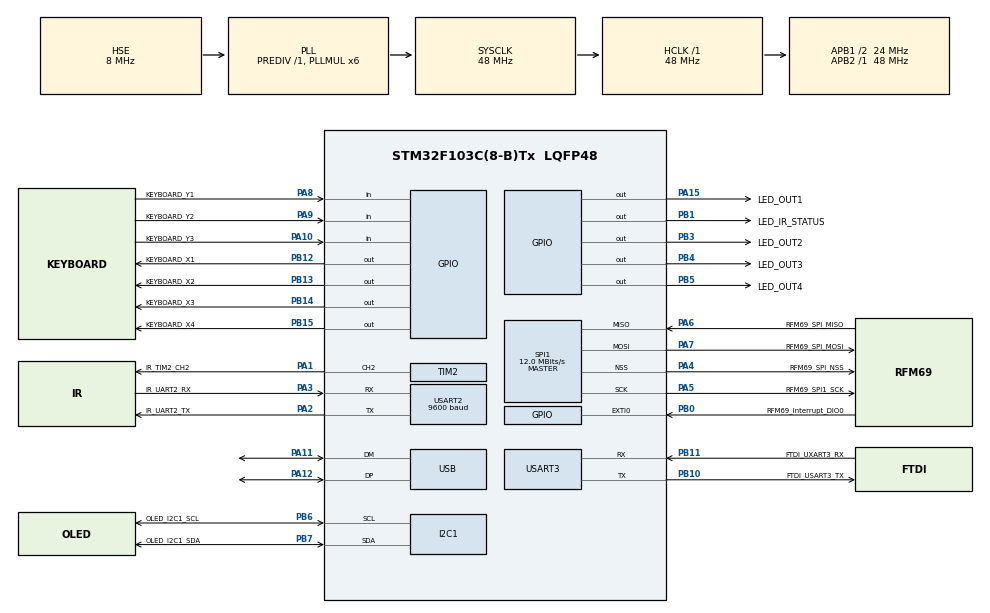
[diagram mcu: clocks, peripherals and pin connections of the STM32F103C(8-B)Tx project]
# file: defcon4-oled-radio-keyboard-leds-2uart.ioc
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Dma.I2C1_RX.3.Direction=DMA_PERIPH_TO_MEMORY
Dma.I2C1_RX.3.Instance=DMA1_Channel7
Dma.I2C1_RX.3.MemDataAlignment=DMA_MDATAALIGN_BYTE
Dma.I2C1_RX.3.MemInc=DMA_MINC_ENABLE
Dma.I2C1_RX.3.Mode=DMA_NORMAL
Dma.I2C1_RX.3.PeriphDataAlignment=DMA_PDATAALIGN_BYTE
Dma.I2C1_RX.3.PeriphInc=DMA_PINC_DISABLE
Dma.I2C1_RX.3.Priority=DMA_PRIORITY_MEDIUM
Dma.I2C1_TX.2.Direction=DMA_MEMORY_TO_PERIPH
Dma.I2C1_TX.2.Instance=DMA1_Channel6
Dma.I2C1_TX.2.MemDataAlignment=DMA_MDATAALIGN_BYTE
Dma.I2C1_TX.2.MemInc=DMA_MINC_ENABLE
Dma.I2C1_TX.2.Mode=DMA_NORMAL
Dma.I2C1_TX.2.PeriphDataAlignment=DMA_PDATAALIGN_BYTE
Dma.I2C1_TX.2.PeriphInc=DMA_PINC_DISABLE
Dma.I2C1_TX.2.Priority=DMA_PRIORITY_MEDIUM
Dma.Request0=SPI1_TX
Dma.Request1=SPI1_RX
Dma.Request2=I2C1_TX
Dma.Request3=I2C1_RX
Dma.SPI1_RX.1.Direction=DMA_PERIPH_TO_MEMORY
Dma.SPI1_RX.1.Instance=DMA1_Channel2
Dma.SPI1_RX.1.MemDataAlignment=DMA_MDATAALIGN_BYTE
Dma.SPI1_RX.1.MemInc=DMA_MINC_ENABLE
Dma.SPI1_RX.1.Mode=DMA_NORMAL
Dma.SPI1_RX.1.PeriphDataAlignment=DMA_PDATAALIGN_BYTE
Dma.SPI1_RX.1.PeriphInc=DMA_PINC_DISABLE
Dma.SPI1_RX.1.Priority=DMA_PRIORITY_HIGH
Dma.SPI1_TX.0.Direction=DMA_MEMORY_TO_PERIPH
Dma.SPI1_TX.0.Instance=DMA1_Channel3
Dma.SPI1_TX.0.MemDataAlignment=DMA_MDATAALIGN_BYTE
Dma.SPI1_TX.0.MemInc=DMA_MINC_ENABLE
Dma.SPI1_TX.0.Mode=DMA_NORMAL
Dma.SPI1_TX.0.PeriphDataAlignment=DMA_PDATAALIGN_BYTE
Dma.SPI1_TX.0.PeriphInc=DMA_PINC_DISABLE
Dma.SPI1_TX.0.Priority=DMA_PRIORITY_HIGH
I2C1.I2C_Mode=I2C_Fast
Mcu.Family=STM32F1
Mcu.Name=STM32F103C(8-B)Tx
Mcu.Package=LQFP48
NVIC.DMA1_Channel2_IRQn=true\:0\:0\:false\:false\:true
NVIC.DMA1_Channel3_IRQn=true\:0\:0\:false\:false\:true
NVIC.DMA1_Channel6_IRQn=true\:0\:0\:false\:false\:true
NVIC.DMA1_Channel7_IRQn=true\:0\:0\:false\:false\:true
NVIC.EXTI0_IRQn=true\:0\:0\:false\:false\:true
NVIC.PriorityGroup=NVIC_PRIORITYGROUP_4
NVIC.USB_LP_CAN1_RX0_IRQn=true\:0\:0\:false\:false\:true
PA1.GPIO_Label=IR_TIM2_CH2
PA1.Signal=S_TIM2_CH2
PA10.GPIO_Label=KEYBOARD_Y3
PA10.GPIO_PuPd=GPIO_PULLUP
PA10.Signal=GPIO_Input
PA11.Mode=Device
PA11.Signal=USB_DM
PA12.Mode=Device
PA12.Signal=USB_DP
PA13.Mode=Serial_Wire
PA13.Signal=SYS_JTMS-SWDIO
PA14.Mode=Serial_Wire
PA14.Signal=SYS_JTCK-SWCLK
PA15.GPIO_Label=LED_OUT1
PA15.Signal=GPIO_Output
PA2.GPIO_Label=IR_UART2_TX
PA2.Mode=Asynchronous
PA2.Signal=USART2_TX
PA3.GPIO_Label=IR_UART2_RX
PA3.Mode=Asynchronous
PA3.Signal=USART2_RX
PA4.GPIO_Label=RFM69_SPI_NSS
PA4.Mode=NSS_Signal_Hard_Output
PA4.Signal=SPI1_NSS
PA5.GPIO_Label=RFM69_SPI1_SCK
PA5.Mode=Full_Duplex_Master
PA5.Signal=SPI1_SCK
PA6.GPIO_Label=RFM69_SPI_MISO
PA6.Mode=Full_Duplex_Master
PA6.Signal=SPI1_MISO
PA7.GPIO_Label=RFM69_SPI_MOSI
PA7.Mode=Full_Duplex_Master
PA7.Signal=SPI1_MOSI
PA8.GPIO_Label=KEYBOARD_Y1
PA8.GPIO_PuPd=GPIO_PULLUP
PA8.Signal=GPIO_Input
PA9.GPIO_Label=KEYBOARD_Y2
PA9.GPIO_PuPd=GPIO_PULLUP
PA9.Signal=GPIO_Input
PB0.GPIO_Label=RFM69_Interrupt_DIO0
PB0.Signal=GPXTI0
PB1.GPIO_Label=LED_IR_STATUS
PB1.Signal=GPIO_Output
PB10.GPIO_Label=FTDI_USART3_TX
PB10.Mode=Asynchronous
PB10.Signal=USART3_TX
PB11.GPIO_Label=FTDI_UXART3_RX
PB11.Mode=Asynchronous
PB11.Signal=USART3_RX
PB12.GPIO_Label=KEYBOARD_X1
PB12.Signal=GPIO_Output
PB13.GPIO_Label=KEYBOARD_X2
PB13.Signal=GPIO_Output
PB14.GPIO_Label=KEYBOARD_X3
PB14.Signal=GPIO_Output
PB15.GPIO_Label=KEYBOARD_X4
PB15.Signal=GPIO_Output
PB3.GPIO_Label=LED_OUT2
PB3.Signal=GPIO_Output
PB4.GPIO_Label=LED_OUT3
PB4.Signal=GPIO_Output
PB5.GPIO_Label=LED_OUT4
PB5.Signal=GPIO_Output
PB6.GPIO_Label=OLED_I2C1_SCL
PB6.Mode=I2C
PB6.Signal=I2C1_SCL
PB7.GPIO_Label=OLED_I2C1_SDA
PB7.Mode=I2C
PB7.Signal=I2C1_SDA
PD0-OSC_IN.Mode=HSE-External-Oscillator
PD0-OSC_IN.Signal=RCC_OSC_IN
PD1-OSC_OUT.Mode=HSE-External-Oscillator
PD1-OSC_OUT.Signal=RCC_OSC_OUT
ProjectManager.HeapSize=0x200
ProjectManager.StackSize=0x400
ProjectManager.TargetToolchain=MDK-ARM V5
RCC.AHBFreq_Value=48000000
RCC.APB1CLKDivider=RCC_HCLK_DIV2
RCC.APB1Freq_Value=24000000
RCC.APB1TimFreq_Value=48000000
RCC.APB2Freq_Value=48000000
RCC.APB2TimFreq_Value=48000000
RCC.HCLKFreq_Value=48000000
RCC.HSIState=RCC_HSI_ON
RCC.PLLMUL=RCC_PLL_MUL6
RCC.SYSCLKFreq_VALUE=48000000
RCC.SYSCLKSource=RCC_SYSCLKSOURCE_PLLCLK
RCC.USBFreq_Value=48000000
SH.S_TIM2_CH2.0=TIM2_CH2,PWM Generation2 CH2
SPI1.BaudRatePrescaler=SPI_BAUDRATEPRESCALER_4
SPI1.CalculateBaudRate=12.0 MBits/s
SPI1.Mode=SPI_MODE_MASTER
SPI1.VirtualNSS=VM_NSSHARD
TIM2.Channel-PWM\ Generation2\ CH2=TIM_CHANNEL_2
TIM2.OCMode_PWM-PWM\ Generation2\ CH2=TIM_OCMODE_PWM1
TIM2.Period=1264
TIM2.Pulse-PWM\ Generation2\ CH2=632
USART2.BaudRate=9600
USB_DEVICE.CLASS_NAME_FS=CDC
USB_DEVICE.USBD_HandleTypeDef=hUsbDeviceFS
USB_DEVICE.VirtualMode=Cdc
USB_DEVICE.VirtualModeFS=Cdc_FS
VP_TIM2_VS_ClockSourceINT.Mode=Internal
VP_USB_DEVICE_VS_USB_DEVICE_CDC_FS.Mode=CDC_FS
board=defcon4-oled-radio-keyboard-leds-2uart

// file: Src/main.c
/**
  ******************************************************************************
  * File Name          : main.c
  * Description        : Main program body
  ******************************************************************************
  *
  * COPYRIGHT(c) 2016 STMicroelectronics
  *
  * Redistribution and use in source and binary forms, with or without modification,
  * are permitted provided that the following conditions are met:
  *   1. Redistributions of source code must retain the above copyright notice,
  *      this list of conditions and the following disclaimer.
  *   2. Redistributions in binary form must reproduce the above copyright notice,
  *      this list of conditions and the following disclaimer in the documentation
  *      and/or other materials provided with the distribution.
  *   3. Neither the name of STMicroelectronics nor the names of its contributors
  *      may be used to endorse or promote products derived from this software
  *      without specific prior written permission.
  *
  * THIS SOFTWARE IS PROVIDED BY THE COPYRIGHT HOLDERS AND CONTRIBUTORS "AS IS"
  * AND ANY EXPRESS OR IMPLIED WARRANTIES, INCLUDING, BUT NOT LIMITED TO, THE
  * IMPLIED WARRANTIES OF MERCHANTABILITY AND FITNESS FOR A PARTICULAR PURPOSE ARE
  * DISCLAIMED. IN NO EVENT SHALL THE COPYRIGHT HOLDER OR CONTRIBUTORS BE LIABLE
  * FOR ANY DIRECT, INDIRECT, INCIDENTAL, SPECIAL, EXEMPLARY, OR CONSEQUENTIAL
  * DAMAGES (INCLUDING, BUT NOT LIMITED TO, PROCUREMENT OF SUBSTITUTE GOODS OR
  * SERVICES; LOSS OF USE, DATA, OR PROFITS; OR BUSINESS INTERRUPTION) HOWEVER
  * CAUSED AND ON ANY THEORY OF LIABILITY, WHETHER IN CONTRACT, STRICT LIABILITY,
  * OR TORT (INCLUDING NEGLIGENCE OR OTHERWISE) ARISING IN ANY WAY OUT OF THE USE
  * OF THIS SOFTWARE, EVEN IF ADVISED OF THE POSSIBILITY OF SUCH DAMAGE.
  *
  ******************************************************************************
  */
#include "stm32f1xx_hal.h"
#include "dma.h"
#include "i2c.h"
#include "spi.h"
#include "tim.h"
#include "usart.h"
#include "usb_device.h"
#include "gpio.h"

/* USER CODE BEGIN Includes */
#include <badge.h>
/* USER CODE END Includes */

/* USER CODE BEGIN PV */
/* Private variables ---------------------------------------------------------*/

/* USER CODE END PV */

void SystemClock_Config(void);

/* USER CODE BEGIN PFP */
/* Private function prototypes -----------------------------------------------*/

/* USER CODE END PFP */

int main(void)
{

  /* USER CODE BEGIN 1 */
	//printf("hello!");
  /* USER CODE END 1 */

  /* MCU Configuration----------------------------------------------------------*/

  /* Reset of all peripherals, Initializes the Flash interface and the Systick. */
  HAL_Init();

  /* Configure the system clock */
  SystemClock_Config();

  /* Initialize all configured peripherals */
  MX_GPIO_Init();
  MX_DMA_Init();
  MX_SPI1_Init();
  MX_I2C1_Init();
  MX_USB_DEVICE_Init();
  MX_USART2_UART_Init();
  MX_USART3_UART_Init();
  MX_TIM2_Init();

  /* USER CODE BEGIN 2 */
	startBadge();
  /* USER CODE END 2 */

  /* Infinite loop */
  while (1)
  {

  /* USER CODE BEGIN 3 */
		loopBadge();
  }
  /* USER CODE END 3 */

}

/** System Clock Configuration
*/
void SystemClock_Config(void)
{

  RCC_OscInitTypeDef RCC_OscInitStruct;
  RCC_ClkInitTypeDef RCC_ClkInitStruct;
  RCC_PeriphCLKInitTypeDef PeriphClkInit;

  RCC_OscInitStruct.OscillatorType = RCC_OSCILLATORTYPE_HSE;
  RCC_OscInitStruct.HSEState = RCC_HSE_ON;
  RCC_OscInitStruct.HSEPredivValue = RCC_HSE_PREDIV_DIV1;
  RCC_OscInitStruct.PLL.PLLState = RCC_PLL_ON;
  RCC_OscInitStruct.PLL.PLLSource = RCC_PLLSOURCE_HSE;
  RCC_OscInitStruct.PLL.PLLMUL = RCC_PLL_MUL6;
  HAL_RCC_OscConfig(&RCC_OscInitStruct);

  RCC_ClkInitStruct.ClockType = RCC_CLOCKTYPE_HCLK|RCC_CLOCKTYPE_SYSCLK
                              |RCC_CLOCKTYPE_PCLK1|RCC_CLOCKTYPE_PCLK2;
  RCC_ClkInitStruct.SYSCLKSource = RCC_SYSCLKSOURCE_PLLCLK;
  RCC_ClkInitStruct.AHBCLKDivider = RCC_SYSCLK_DIV1;
  RCC_ClkInitStruct.APB1CLKDivider = RCC_HCLK_DIV2;
  RCC_ClkInitStruct.APB2CLKDivider = RCC_HCLK_DIV1;
  HAL_RCC_ClockConfig(&RCC_ClkInitStruct, FLASH_LATENCY_1);

  PeriphClkInit.PeriphClockSelection = RCC_PERIPHCLK_USB;
  PeriphClkInit.UsbClockSelection = RCC_USBCLKSOURCE_PLL;
  HAL_RCCEx_PeriphCLKConfig(&PeriphClkInit);

  HAL_SYSTICK_Config(HAL_RCC_GetHCLKFreq()/1000);

  HAL_SYSTICK_CLKSourceConfig(SYSTICK_CLKSOURCE_HCLK);

  /* SysTick_IRQn interrupt configuration */
  HAL_NVIC_SetPriority(SysTick_IRQn, 0, 0);
}

/************************ (C) COPYRIGHT STMicroelectronics *****END OF FILE****/
